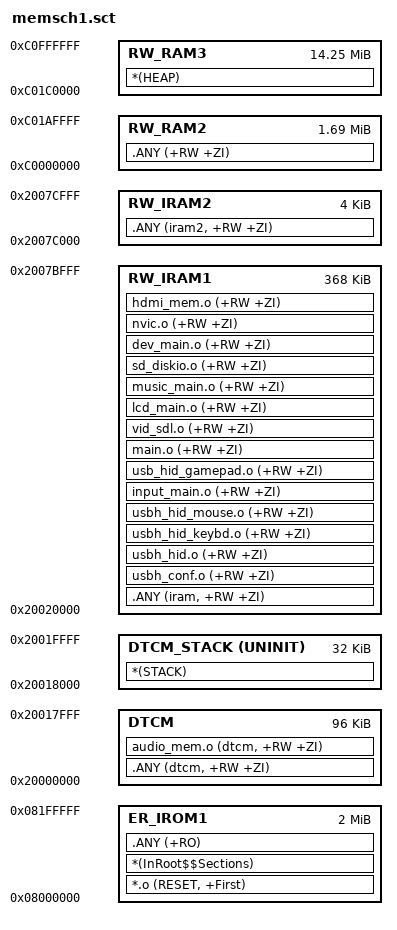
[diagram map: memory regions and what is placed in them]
; *************************************************************
; *** Scatter-Loading Description File generated by uVision ***
; *************************************************************

LR_IROM1 0x08000000 0x00200000  {    ; load region size_region
  ER_IROM1 0x08000000 0x00200000  {  ; load address = execution address
   *.o (RESET, +First)
   *(InRoot$$Sections)
   .ANY (+RO)
  }
  DTCM 0x20000000 0x00018000  {  ; DTCM
   .ANY (dtcm, +RW +ZI)
   audio_mem.o (dtcm, +RW +ZI)
   ;r_main.o (dtcm, +RW +ZI)
  }
  DTCM_STACK 0x20018000 UNINIT 0x00008000  {  ; DTCM
   *(STACK)
  }
  RW_IRAM1 0x20020000 0x0005C000  {  ; RW data
   .ANY (iram, +RW +ZI)
   usbh_conf.o (+RW +ZI)
   ;usbh_core.o (+RW +ZI)
   ;usbh_ctlrec.o (+RW +ZI)
   usbh_hid.o (+RW +ZI)
   usbh_hid_keybd.o (+RW +ZI)
   usbh_hid_mouse.o (+RW +ZI)
   ;usbh_hid_parser.o (+RW +ZI)
   ;usbh_ioreq.o (+RW +ZI)
   ;usbh_pipes.o (+RW +ZI)
   input_main.o (+RW +ZI)
   usb_hid_gamepad.o (+RW +ZI)
   main.o (+RW +ZI)
   vid_sdl.o (+RW +ZI)
   ;sys_sdl.o (+RW +ZI)
   ;snd_mem.o (+RW +ZI)
   ;snd_mix.o (+RW +ZI)
   lcd_main.o (+RW +ZI)
   ;audio_ext.o (+RW +ZI)
   ;audio_mix.o (+RW +ZI)
   music_main.o (+RW +ZI)
   sd_diskio.o (+RW +ZI)
   dev_main.o (+RW +ZI)
   nvic.o (+RW +ZI)
   hdmi_mem.o (+RW +ZI)
  }
  RW_IRAM2 0x2007C000 0x00001000  {  ; RW data
   .ANY (iram2, +RW +ZI)
  }
  RW_RAM2 0xc0000000 0x001b0000  {  ; RW data
   .ANY (+RW +ZI)
  }
  RW_RAM3 0xC01c0000 0x00e40000  { ; External SDRAM
   *(HEAP)
  }
}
